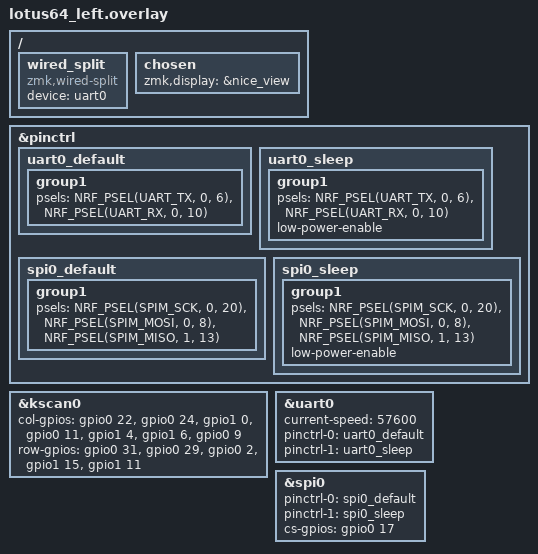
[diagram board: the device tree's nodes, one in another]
/*
 * lotus64_left.overlay - Left half specific configuration
 */

#include "lotus64.dtsi"

&pinctrl {
    // UART for split communication (USB-C external port)
    uart0_default: uart0_default {
        group1 {
            psels = <NRF_PSEL(UART_TX, 0, 6)>,
                    <NRF_PSEL(UART_RX, 0, 10)>;
        };
    };

    uart0_sleep: uart0_sleep {
        group1 {
            psels = <NRF_PSEL(UART_TX, 0, 6)>,
                    <NRF_PSEL(UART_RX, 0, 10)>;
            low-power-enable;
        };
    };

    // SPI for Nice!View
    spi0_default: spi0_default {
        group1 {
            psels = <NRF_PSEL(SPIM_SCK, 0, 20)>,
                    <NRF_PSEL(SPIM_MOSI, 0, 8)>,
                    <NRF_PSEL(SPIM_MISO, 1, 13)>;
        };
    };
    spi0_sleep: spi0_sleep {
        group1 {
            psels = <NRF_PSEL(SPIM_SCK, 0, 20)>,
                    <NRF_PSEL(SPIM_MOSI, 0, 8)>,
                    <NRF_PSEL(SPIM_MISO, 1, 13)>;
            low-power-enable;
        };
    };
};

// Matrix configuration
&kscan0 {
    col-gpios
        = <&gpio0 22  GPIO_ACTIVE_HIGH>  // col 0
        , <&gpio0 24  GPIO_ACTIVE_HIGH>  // col 1
        , <&gpio1 0   GPIO_ACTIVE_HIGH>  // col 2
        , <&gpio0 11  GPIO_ACTIVE_HIGH>  // col 3
        , <&gpio1 4   GPIO_ACTIVE_HIGH>  // col 4
        , <&gpio1 6   GPIO_ACTIVE_HIGH>  // col 5
        , <&gpio0 9   GPIO_ACTIVE_HIGH>  // col 6
        ;

    row-gpios
        = <&gpio0 31 (GPIO_ACTIVE_HIGH | GPIO_PULL_DOWN)>  // row 0
        , <&gpio0 29 (GPIO_ACTIVE_HIGH | GPIO_PULL_DOWN)>  // row 1
        , <&gpio0 2  (GPIO_ACTIVE_HIGH | GPIO_PULL_DOWN)>  // row 2
        , <&gpio1 15 (GPIO_ACTIVE_HIGH | GPIO_PULL_DOWN)>  // row 3
        , <&gpio1 11 (GPIO_ACTIVE_HIGH | GPIO_PULL_DOWN)>  // row 4
        ;
};

// UART configuration for split communication
&uart0 {
    status = "okay";
    current-speed = <57600>;
    pinctrl-0 = <&uart0_default>;
    pinctrl-1 = <&uart0_sleep>;
    pinctrl-names = "default", "sleep";
};

// SPI configuration for Nice!View
&spi0 {
    status = "okay";
    pinctrl-0 = <&spi0_default>;
    pinctrl-1 = <&spi0_sleep>;
    pinctrl-names = "default", "sleep";
    cs-gpios = <&gpio0 17 GPIO_ACTIVE_HIGH>;
};

nice_view_spi: &spi0 {};

// Split keyboard configuration
/ {
    wired_split {
        compatible = "zmk,wired-split";
        device     = <&uart0>;
    };

    chosen {
        zmk,display = &nice_view;
    };
};
